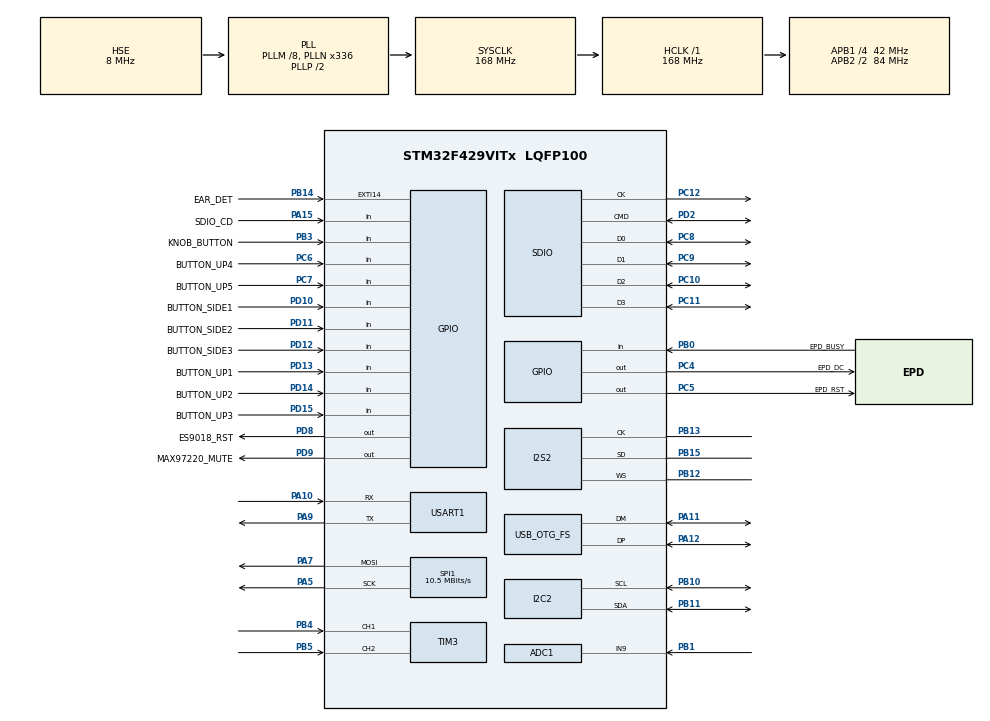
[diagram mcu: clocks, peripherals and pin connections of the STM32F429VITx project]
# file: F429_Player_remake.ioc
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ADC1.Channel-9\#ChannelRegularConversion=ADC_CHANNEL_9
ADC1.ClockPrescaler=ADC_CLOCK_SYNC_PCLK_DIV4
ADC1.NbrOfConversionFlag=1
ADC1.Rank-9\#ChannelRegularConversion=1
ADC1.SamplingTime-9\#ChannelRegularConversion=ADC_SAMPLETIME_480CYCLES
ADC1.master=1
Dma.Request0=SPI1_TX
Dma.Request1=USART1_RX
Dma.Request2=USART1_TX
Dma.Request3=SPI2_TX
Dma.Request4=SDIO
Dma.SDIO.4.Direction=DMA_PERIPH_TO_MEMORY
Dma.SDIO.4.FIFOMode=DMA_FIFOMODE_ENABLE
Dma.SDIO.4.FIFOThreshold=DMA_FIFO_THRESHOLD_FULL
Dma.SDIO.4.Instance=DMA2_Stream6
Dma.SDIO.4.MemBurst=DMA_MBURST_INC4
Dma.SDIO.4.MemDataAlignment=DMA_MDATAALIGN_WORD
Dma.SDIO.4.MemInc=DMA_MINC_ENABLE
Dma.SDIO.4.Mode=DMA_PFCTRL
Dma.SDIO.4.PeriphBurst=DMA_PBURST_INC4
Dma.SDIO.4.PeriphDataAlignment=DMA_PDATAALIGN_WORD
Dma.SDIO.4.PeriphInc=DMA_PINC_DISABLE
Dma.SDIO.4.Priority=DMA_PRIORITY_LOW
Dma.SPI1_TX.0.Direction=DMA_MEMORY_TO_PERIPH
Dma.SPI1_TX.0.FIFOMode=DMA_FIFOMODE_DISABLE
Dma.SPI1_TX.0.Instance=DMA2_Stream3
Dma.SPI1_TX.0.MemDataAlignment=DMA_MDATAALIGN_BYTE
Dma.SPI1_TX.0.MemInc=DMA_MINC_ENABLE
Dma.SPI1_TX.0.Mode=DMA_NORMAL
Dma.SPI1_TX.0.PeriphDataAlignment=DMA_PDATAALIGN_BYTE
Dma.SPI1_TX.0.PeriphInc=DMA_PINC_DISABLE
Dma.SPI1_TX.0.Priority=DMA_PRIORITY_LOW
Dma.SPI2_TX.3.Direction=DMA_MEMORY_TO_PERIPH
Dma.SPI2_TX.3.FIFOMode=DMA_FIFOMODE_DISABLE
Dma.SPI2_TX.3.Instance=DMA1_Stream4
Dma.SPI2_TX.3.MemDataAlignment=DMA_MDATAALIGN_HALFWORD
Dma.SPI2_TX.3.MemInc=DMA_MINC_ENABLE
Dma.SPI2_TX.3.Mode=DMA_CIRCULAR
Dma.SPI2_TX.3.PeriphDataAlignment=DMA_PDATAALIGN_HALFWORD
Dma.SPI2_TX.3.PeriphInc=DMA_PINC_DISABLE
Dma.SPI2_TX.3.Priority=DMA_PRIORITY_VERY_HIGH
Dma.USART1_RX.1.Direction=DMA_PERIPH_TO_MEMORY
Dma.USART1_RX.1.FIFOMode=DMA_FIFOMODE_DISABLE
Dma.USART1_RX.1.Instance=DMA2_Stream2
Dma.USART1_RX.1.MemDataAlignment=DMA_MDATAALIGN_BYTE
Dma.USART1_RX.1.MemInc=DMA_MINC_ENABLE
Dma.USART1_RX.1.Mode=DMA_NORMAL
Dma.USART1_RX.1.PeriphDataAlignment=DMA_PDATAALIGN_BYTE
Dma.USART1_RX.1.PeriphInc=DMA_PINC_DISABLE
Dma.USART1_RX.1.Priority=DMA_PRIORITY_LOW
Dma.USART1_TX.2.Direction=DMA_MEMORY_TO_PERIPH
Dma.USART1_TX.2.FIFOMode=DMA_FIFOMODE_DISABLE
Dma.USART1_TX.2.Instance=DMA2_Stream7
Dma.USART1_TX.2.MemDataAlignment=DMA_MDATAALIGN_BYTE
Dma.USART1_TX.2.MemInc=DMA_MINC_ENABLE
Dma.USART1_TX.2.Mode=DMA_NORMAL
Dma.USART1_TX.2.PeriphDataAlignment=DMA_PDATAALIGN_BYTE
Dma.USART1_TX.2.PeriphInc=DMA_PINC_DISABLE
Dma.USART1_TX.2.Priority=DMA_PRIORITY_LOW
FREERTOS.Tasks01=defaultTask,24,1024,StartDefaultTask,Default,NULL,Dynamic,NULL,NULL
FREERTOS.configTOTAL_HEAP_SIZE=40960
I2S2.AudioFreq=I2S_AUDIOFREQ_48K
I2S2.ErrorAudioFreq=-0.01 %
I2S2.FullDuplexMode=I2S_FULLDUPLEXMODE_DISABLE
I2S2.Instance=SPI$Index
I2S2.RealAudioFreq=47.991 KHz
I2S2.VirtualMode=I2S_MODE_MASTER
Mcu.Family=STM32F4
Mcu.Name=STM32F429VITx
Mcu.Package=LQFP100
NVIC.DMA1_Stream4_IRQn=true\:5\:0\:false\:false\:true\:true\:false\:true\:true
NVIC.DMA2_Stream2_IRQn=true\:5\:0\:false\:false\:true\:true\:false\:true\:true
NVIC.DMA2_Stream3_IRQn=true\:5\:0\:false\:false\:true\:true\:false\:true\:true
NVIC.DMA2_Stream6_IRQn=true\:5\:0\:false\:false\:true\:true\:false\:true\:true
NVIC.DMA2_Stream7_IRQn=true\:5\:0\:false\:false\:true\:true\:false\:true\:true
NVIC.EXTI15_10_IRQn=true\:5\:0\:false\:false\:true\:true\:false\:true\:true
NVIC.OTG_FS_IRQn=true\:5\:0\:false\:false\:true\:true\:true\:true\:true
NVIC.PriorityGroup=NVIC_PRIORITYGROUP_4
NVIC.SDIO_IRQn=true\:5\:0\:false\:false\:true\:true\:true\:true\:true
NVIC.SPI1_IRQn=true\:5\:0\:false\:false\:true\:true\:true\:true\:true
NVIC.SPI2_IRQn=true\:5\:0\:false\:false\:true\:true\:true\:true\:true
NVIC.TIM8_TRG_COM_TIM14_IRQn=true\:15\:0\:false\:false\:true\:false\:false\:true\:true
NVIC.TimeBase=TIM8_TRG_COM_TIM14_IRQn
NVIC.TimeBaseIP=TIM14
NVIC.USART1_IRQn=true\:5\:0\:false\:false\:true\:true\:false\:true\:true
PA10.Mode=Asynchronous
PA10.Signal=USART1_RX
PA11.Mode=Device_Only
PA11.Signal=USB_OTG_FS_DM
PA12.Mode=Device_Only
PA12.Signal=USB_OTG_FS_DP
PA13.Mode=Serial_Wire
PA13.Signal=SYS_JTMS-SWDIO
PA14.Mode=Serial_Wire
PA14.Signal=SYS_JTCK-SWCLK
PA15.GPIO_Label=SDIO_CD
PA15.GPIO_PuPd=GPIO_PULLUP
PA15.Signal=GPIO_Input
PA5.Mode=TX_Only_Simplex_Unidirect_Master
PA5.Signal=SPI1_SCK
PA7.Mode=TX_Only_Simplex_Unidirect_Master
PA7.Signal=SPI1_MOSI
PA9.Mode=Asynchronous
PA9.Signal=USART1_TX
PB0.GPIO_Label=EPD_BUSY
PB0.GPIO_PuPd=GPIO_PULLUP
PB0.Signal=GPIO_Input
PB1.Signal=ADCx_IN9
PB10.GPIO_Pu=GPIO_PULLUP
PB10.Mode=I2C
PB10.Signal=I2C2_SCL
PB11.GPIO_Pu=GPIO_PULLUP
PB11.Mode=I2C
PB11.Signal=I2C2_SDA
PB12.Mode=Half_Duplex_Master
PB12.Signal=I2S2_WS
PB13.Mode=Half_Duplex_Master
PB13.Signal=I2S2_CK
PB14.GPIO_ModeDefaultEXTI=GPIO_MODE_IT_RISING_FALLING
PB14.GPIO_Label=EAR_DET
PB14.GPIO_PuPd=GPIO_PULLUP
PB14.Signal=GPXTI14
PB15.Mode=Half_Duplex_Master
PB15.Signal=I2S2_SD
PB3.GPIO_Label=KNOB_BUTTON
PB3.GPIO_PuPd=GPIO_PULLUP
PB3.Signal=GPIO_Input
PB4.GPIO_PuPd=GPIO_PULLUP
PB4.Signal=S_TIM3_CH1
PB5.GPIO_PuPd=GPIO_PULLUP
PB5.Signal=S_TIM3_CH2
PC10.GPIO_PuPd=GPIO_PULLUP
PC10.Mode=SD_4_bits_Wide_bus
PC10.Signal=SDIO_D2
PC11.GPIO_PuPd=GPIO_PULLUP
PC11.Mode=SD_4_bits_Wide_bus
PC11.Signal=SDIO_D3
PC12.GPIO_PuPd=GPIO_PULLUP
PC12.Mode=SD_4_bits_Wide_bus
PC12.Signal=SDIO_CK
PC4.GPIO_Label=EPD_DC
PC4.Signal=GPIO_Output
PC5.GPIO_Label=EPD_RST
PC5.Signal=GPIO_Output
PC6.GPIO_Label=BUTTON_UP4
PC6.GPIO_PuPd=GPIO_PULLUP
PC6.Signal=GPIO_Input
PC7.GPIO_Label=BUTTON_UP5
PC7.GPIO_PuPd=GPIO_PULLUP
PC7.Signal=GPIO_Input
PC8.GPIO_PuPd=GPIO_PULLUP
PC8.Mode=SD_4_bits_Wide_bus
PC8.Signal=SDIO_D0
PC9.GPIO_PuPd=GPIO_PULLUP
PC9.Mode=SD_4_bits_Wide_bus
PC9.Signal=SDIO_D1
PD10.GPIO_Label=BUTTON_SIDE1
PD10.GPIO_PuPd=GPIO_PULLUP
PD10.Signal=GPIO_Input
PD11.GPIO_Label=BUTTON_SIDE2
PD11.GPIO_PuPd=GPIO_PULLUP
PD11.Signal=GPIO_Input
PD12.GPIO_Label=BUTTON_SIDE3
PD12.GPIO_PuPd=GPIO_PULLUP
PD12.Signal=GPIO_Input
PD13.GPIO_Label=BUTTON_UP1
PD13.GPIO_PuPd=GPIO_PULLUP
PD13.Signal=GPIO_Input
PD14.GPIO_Label=BUTTON_UP2
PD14.GPIO_PuPd=GPIO_PULLUP
PD14.Signal=GPIO_Input
PD15.GPIO_Label=BUTTON_UP3
PD15.GPIO_PuPd=GPIO_PULLUP
PD15.Signal=GPIO_Input
PD2.GPIO_PuPd=GPIO_PULLUP
PD2.Mode=SD_4_bits_Wide_bus
PD2.Signal=SDIO_CMD
PD8.GPIO_Label=ES9018_RST
PD8.PinState=GPIO_PIN_RESET
PD8.Signal=GPIO_Output
PD9.GPIO_Label=MAX97220_MUTE
PD9.Signal=GPIO_Output
PH0/OSC_IN.Mode=HSE-External-Oscillator
PH0/OSC_IN.Signal=RCC_OSC_IN
PH1/OSC_OUT.Mode=HSE-External-Oscillator
PH1/OSC_OUT.Signal=RCC_OSC_OUT
ProjectManager.HeapSize=0x200
ProjectManager.StackSize=0x400
ProjectManager.TargetToolchain=CMake
RCC.48MHZClocksFreq_Value=48000000
RCC.AHBFreq_Value=168000000
RCC.APB1CLKDivider=RCC_HCLK_DIV4
RCC.APB1Freq_Value=42000000
RCC.APB1TimFreq_Value=84000000
RCC.APB2CLKDivider=RCC_HCLK_DIV2
RCC.APB2Freq_Value=84000000
RCC.APB2TimFreq_Value=168000000
RCC.CortexFreq_Value=168000000
RCC.HCLKFreq_Value=168000000
RCC.HSE_VALUE=8000000
RCC.HSI_VALUE=16000000
RCC.LSE_VALUE=32768
RCC.PLLI2SN=258
RCC.PLLI2SR=3
RCC.PLLM=8
RCC.PLLN=336
RCC.PLLQ=7
RCC.PLLSAIN=100
RCC.SYSCLKFreq_VALUE=168000000
RCC.SYSCLKSource=RCC_SYSCLKSOURCE_PLLCLK
RCC.VCOOutputFreq_Value=336000000
SH.ADCx_IN9.0=ADC1_IN9,IN9
SH.S_TIM3_CH1.0=TIM3_CH1,Encoder_Interface
SH.S_TIM3_CH2.0=TIM3_CH2,Encoder_Interface
SPI1.BaudRatePrescaler=SPI_BAUDRATEPRESCALER_8
SPI1.CalculateBaudRate=10.5 MBits/s
SPI1.Direction=SPI_DIRECTION_2LINES
SPI1.Mode=SPI_MODE_MASTER
SPI1.VirtualType=VM_MASTER
TIM3.EncoderMode=TIM_ENCODERMODE_TI12
USART1.VirtualMode=VM_ASYNC
USB_DEVICE.CLASS_NAME_FS=AUDIO
USB_DEVICE.USBD_AUDIO_FREQ-AUDIO_FS=96000
USB_DEVICE.VirtualMode-AUDIO_FS=Audio
USB_DEVICE.VirtualModeFS=Audio_FS
USB_OTG_FS.Sof_enable=ENABLE
USB_OTG_FS.VirtualMode=Device_Only
VP_FREERTOS_VS_CMSIS_V2.Mode=CMSIS_V2
VP_SYS_VS_tim14.Mode=TIM14
VP_USB_DEVICE_VS_USB_DEVICE_AUDIO_FS.Mode=AUDIO_FS
board=custom

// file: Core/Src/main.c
/* USER CODE BEGIN Header */
/**
  ******************************************************************************
  * @file           : main.c
  * @brief          : Main program body
  ******************************************************************************
  * @attention
  *
  * Copyright (c) 2026 STMicroelectronics.
  * All rights reserved.
  *
  * This software is licensed under terms that can be found in the LICENSE file
  * in the root directory of this software component.
  * If no LICENSE file comes with this software, it is provided AS-IS.
  *
  ******************************************************************************
  */
/* USER CODE END Header */
#include "main.h"
#include "cmsis_os.h"
#include "adc.h"
#include "dma.h"
#include "i2c.h"
#include "i2s.h"
#include "sdio.h"
#include "spi.h"
#include "tim.h"
#include "usart.h"
#include "usb_device.h"
#include "gpio.h"

void SystemClock_Config(void);
void MX_FREERTOS_Init(void);

int main(void)
{

  /* MCU Configuration--------------------------------------------------------*/

  /* Reset of all peripherals, Initializes the Flash interface and the Systick. */
  HAL_Init();

  /* Configure the system clock */
  SystemClock_Config();

  /* Initialize all configured peripherals */
  MX_GPIO_Init();
  MX_DMA_Init();
  MX_SPI1_Init();
  MX_USART1_UART_Init();
  MX_I2S2_Init();
  MX_SDIO_SD_Init();
  MX_I2C2_Init();
  MX_TIM3_Init();
  MX_ADC1_Init();

  /* Init scheduler */
  osKernelInitialize();  /* Call init function for freertos objects (in cmsis_os2.c) */
  MX_FREERTOS_Init();

  /* Start scheduler */
  osKernelStart();

  /* We should never get here as control is now taken by the scheduler */

  /* Infinite loop */
  while (1)
  {

  }
}

void SystemClock_Config(void)
{
  RCC_OscInitTypeDef RCC_OscInitStruct = {0};
  RCC_ClkInitTypeDef RCC_ClkInitStruct = {0};

  /** Configure the main internal regulator output voltage
  */
  __HAL_RCC_PWR_CLK_ENABLE();
  __HAL_PWR_VOLTAGESCALING_CONFIG(PWR_REGULATOR_VOLTAGE_SCALE1);

  /** Initializes the RCC Oscillators according to the specified parameters
  * in the RCC_OscInitTypeDef structure.
  */
  RCC_OscInitStruct.OscillatorType = RCC_OSCILLATORTYPE_HSE;
  RCC_OscInitStruct.HSEState = RCC_HSE_ON;
  RCC_OscInitStruct.PLL.PLLState = RCC_PLL_ON;
  RCC_OscInitStruct.PLL.PLLSource = RCC_PLLSOURCE_HSE;
  RCC_OscInitStruct.PLL.PLLM = 8;
  RCC_OscInitStruct.PLL.PLLN = 336;
  RCC_OscInitStruct.PLL.PLLP = RCC_PLLP_DIV2;
  RCC_OscInitStruct.PLL.PLLQ = 7;
  if (HAL_RCC_OscConfig(&RCC_OscInitStruct) != HAL_OK)
  {
    Error_Handler();
  }

  /** Initializes the CPU, AHB and APB buses clocks
  */
  RCC_ClkInitStruct.ClockType = RCC_CLOCKTYPE_HCLK|RCC_CLOCKTYPE_SYSCLK
                              |RCC_CLOCKTYPE_PCLK1|RCC_CLOCKTYPE_PCLK2;
  RCC_ClkInitStruct.SYSCLKSource = RCC_SYSCLKSOURCE_PLLCLK;
  RCC_ClkInitStruct.AHBCLKDivider = RCC_SYSCLK_DIV1;
  RCC_ClkInitStruct.APB1CLKDivider = RCC_HCLK_DIV4;
  RCC_ClkInitStruct.APB2CLKDivider = RCC_HCLK_DIV2;

  if (HAL_RCC_ClockConfig(&RCC_ClkInitStruct, FLASH_LATENCY_5) != HAL_OK)
  {
    Error_Handler();
  }
}

void HAL_TIM_PeriodElapsedCallback(TIM_HandleTypeDef *htim)
{
  if (htim->Instance == TIM14)
  {
    HAL_IncTick();
  }
}

void Error_Handler(void)
{
  __disable_irq();
  while (1)
  {
  }
}

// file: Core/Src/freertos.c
/* USER CODE BEGIN Header */
/**
  ******************************************************************************
  * File Name          : freertos.c
  * Description        : Code for freertos applications
  ******************************************************************************
  * @attention
  *
  * Copyright (c) 2026 STMicroelectronics.
  * All rights reserved.
  *
  * This software is licensed under terms that can be found in the LICENSE file
  * in the root directory of this software component.
  * If no LICENSE file comes with this software, it is provided AS-IS.
  *
  ******************************************************************************
  */
/* USER CODE END Header */

#include "FreeRTOS.h"
#include "task.h"
#include "main.h"
#include "cmsis_os.h"

/* USER CODE BEGIN Variables */
uint8_t ucHeap[configTOTAL_HEAP_SIZE] __attribute__((section(".freertos_heap")));
/* USER CODE END Variables */
/* Definitions for defaultTask */
osThreadId_t defaultTaskHandle;
const osThreadAttr_t defaultTask_attributes = {
  .name = "defaultTask",
  .stack_size = 1024 * 4,
  .priority = (osPriority_t) osPriorityNormal,
};

/* USER CODE BEGIN FunctionPrototypes */
void app_main(void);

/* USER CODE END FunctionPrototypes */

void StartDefaultTask(void *argument);

extern void MX_USB_DEVICE_Init(void);
void MX_FREERTOS_Init(void); /* (MISRA C 2004 rule 8.1) */

void MX_FREERTOS_Init(void) {

  /* Create the thread(s) */
  /* creation of defaultTask */
  defaultTaskHandle = osThreadNew(StartDefaultTask, NULL, &defaultTask_attributes);

}

void StartDefaultTask(void *argument)
{
  /* init code for USB_DEVICE */
  MX_USB_DEVICE_Init();
  /* USER CODE BEGIN StartDefaultTask */
  app_main();
  vTaskDelete(NULL);
  /* USER CODE END StartDefaultTask */
}
